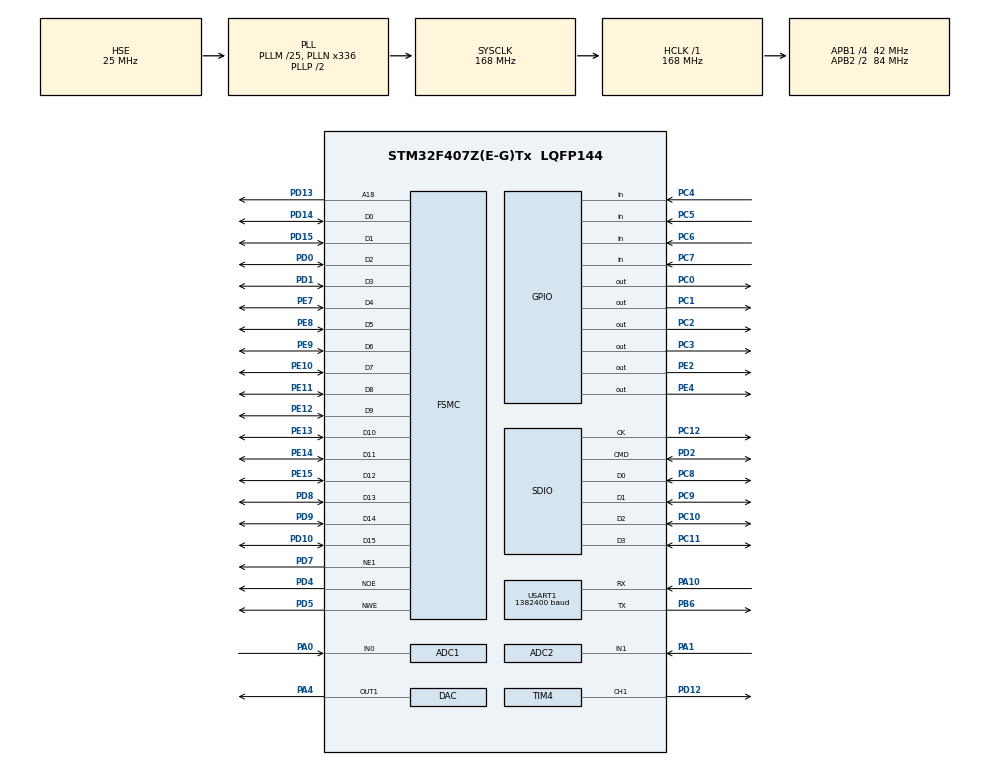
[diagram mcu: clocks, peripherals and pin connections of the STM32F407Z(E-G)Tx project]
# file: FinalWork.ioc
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ADC1.Channel-0\#ChannelRegularConversion=ADC_CHANNEL_0
ADC1.ClockPrescaler=ADC_CLOCK_SYNC_PCLK_DIV4
ADC1.ContinuousConvMode=ENABLE
ADC1.DMAContinuousRequests=ENABLE
ADC1.ExternalTrigConv=ADC_EXTERNALTRIGCONV_T2_TRGO
ADC1.NbrOfConversionFlag=1
ADC1.Rank-0\#ChannelRegularConversion=1
ADC1.SamplingTime-0\#ChannelRegularConversion=ADC_SAMPLETIME_15CYCLES
ADC1.ScanConvMode=DISABLE
ADC1.master=1
ADC2.Channel-1\#ChannelRegularConversion=ADC_CHANNEL_1
ADC2.ClockPrescaler=ADC_CLOCK_SYNC_PCLK_DIV4
ADC2.ExternalTrigConv=ADC_EXTERNALTRIGCONV_T3_TRGO
ADC2.NbrOfConversionFlag=1
ADC2.Rank-1\#ChannelRegularConversion=1
ADC2.SamplingTime-1\#ChannelRegularConversion=ADC_SAMPLETIME_3CYCLES
Dma.ADC1.0.Direction=DMA_PERIPH_TO_MEMORY
Dma.ADC1.0.FIFOMode=DMA_FIFOMODE_DISABLE
Dma.ADC1.0.Instance=DMA2_Stream0
Dma.ADC1.0.MemDataAlignment=DMA_MDATAALIGN_HALFWORD
Dma.ADC1.0.MemInc=DMA_MINC_ENABLE
Dma.ADC1.0.Mode=DMA_NORMAL
Dma.ADC1.0.PeriphDataAlignment=DMA_PDATAALIGN_HALFWORD
Dma.ADC1.0.PeriphInc=DMA_PINC_DISABLE
Dma.ADC1.0.Priority=DMA_PRIORITY_LOW
Dma.ADC2.1.Direction=DMA_PERIPH_TO_MEMORY
Dma.ADC2.1.FIFOMode=DMA_FIFOMODE_DISABLE
Dma.ADC2.1.Instance=DMA2_Stream2
Dma.ADC2.1.MemDataAlignment=DMA_MDATAALIGN_HALFWORD
Dma.ADC2.1.MemInc=DMA_MINC_ENABLE
Dma.ADC2.1.Mode=DMA_NORMAL
Dma.ADC2.1.PeriphDataAlignment=DMA_PDATAALIGN_HALFWORD
Dma.ADC2.1.PeriphInc=DMA_PINC_DISABLE
Dma.ADC2.1.Priority=DMA_PRIORITY_LOW
Dma.Request0=ADC1
Dma.Request1=ADC2
FATFS._FS_RPATH=0
FATFS._STRF_ENCODE=3
FATFS._USE_EXPAND=0
FATFS._USE_FIND=0
FATFS._USE_LFN=0
FSMC.BusTurnAroundDuration1=0
FSMC.DataSetupTime1=24
FSMC.ExtendedAddressSetupTime1=3
FSMC.ExtendedBusTurnAroundDuration1=0
FSMC.ExtendedDataSetupTime1=2
FSMC.ExtendedMode1=FSMC_EXTENDED_MODE_ENABLE
Mcu.Family=STM32F4
Mcu.Name=STM32F407Z(E-G)Tx
Mcu.Package=LQFP144
NVIC.ADC_IRQn=true\:0\:0\:false\:false\:true\:true\:true
NVIC.DMA2_Stream0_IRQn=true\:0\:0\:false\:false\:true\:false\:true
NVIC.DMA2_Stream2_IRQn=true\:0\:0\:false\:false\:true\:false\:true
NVIC.PriorityGroup=NVIC_PRIORITYGROUP_4
NVIC.USART1_IRQn=true\:1\:0\:true\:false\:true\:true\:true
PA0-WKUP.Signal=ADCx_IN0
PA1.Signal=ADCx_IN1
PA10.Mode=Asynchronous
PA10.Signal=USART1_RX
PA13.Mode=Serial_Wire
PA13.Signal=SYS_JTMS-SWDIO
PA14.Mode=Serial_Wire
PA14.Signal=SYS_JTCK-SWCLK
PA4.Signal=COMP_DAC1_group
PB6.Mode=Asynchronous
PB6.Signal=USART1_TX
PC0.Signal=GPIO_Output
PC1.Signal=GPIO_Output
PC10.Mode=SD_4_bits_Wide_bus
PC10.Signal=SDIO_D2
PC11.Mode=SD_4_bits_Wide_bus
PC11.Signal=SDIO_D3
PC12.Mode=SD_4_bits_Wide_bus
PC12.Signal=SDIO_CK
PC2.Signal=GPIO_Output
PC3.Signal=GPIO_Output
PC4.GPIO_PuPd=GPIO_PULLUP
PC4.Signal=GPIO_Input
PC5.GPIO_PuPd=GPIO_PULLUP
PC5.Signal=GPIO_Input
PC6.GPIO_PuPd=GPIO_PULLUP
PC6.Signal=GPIO_Input
PC7.GPIO_PuPd=GPIO_PULLUP
PC7.Signal=GPIO_Input
PC8.Mode=SD_4_bits_Wide_bus
PC8.Signal=SDIO_D0
PC9.Mode=SD_4_bits_Wide_bus
PC9.Signal=SDIO_D1
PD0.Signal=FSMC_D2_DA2
PD1.Signal=FSMC_D3_DA3
PD10.Signal=FSMC_D15_DA15
PD12.Signal=S_TIM4_CH1
PD13.Signal=FSMC_A18
PD14.Signal=FSMC_D0_DA0
PD15.Signal=FSMC_D1_DA1
PD2.Mode=SD_4_bits_Wide_bus
PD2.Signal=SDIO_CMD
PD4.Signal=FSMC_NOE
PD5.Signal=FSMC_NWE
PD7.Mode=NorPsramChipSelect1_1
PD7.Signal=FSMC_NE1
PD8.Signal=FSMC_D13_DA13
PD9.Signal=FSMC_D14_DA14
PE10.Signal=FSMC_D7_DA7
PE11.Signal=FSMC_D8_DA8
PE12.Signal=FSMC_D9_DA9
PE13.Signal=FSMC_D10_DA10
PE14.Signal=FSMC_D11_DA11
PE15.Signal=FSMC_D12_DA12
PE2.Signal=GPIO_Output
PE4.Signal=GPIO_Output
PE7.Signal=FSMC_D4_DA4
PE8.Signal=FSMC_D5_DA5
PE9.Signal=FSMC_D6_DA6
PH0-OSC_IN.Mode=HSE-External-Clock-Source
PH0-OSC_IN.Signal=RCC_OSC_IN
PH1-OSC_OUT.Mode=HSE-External-Clock-Source
PH1-OSC_OUT.Signal=RCC_OSC_OUT
ProjectManager.HeapSize=0x11170
ProjectManager.StackSize=0x11170
ProjectManager.TargetToolchain=MDK-ARM V5.27
RCC.48MHZClocksFreq_Value=48000000
RCC.AHBFreq_Value=168000000
RCC.APB1CLKDivider=RCC_HCLK_DIV4
RCC.APB1Freq_Value=42000000
RCC.APB1TimFreq_Value=84000000
RCC.APB2CLKDivider=RCC_HCLK_DIV2
RCC.APB2Freq_Value=84000000
RCC.APB2TimFreq_Value=168000000
RCC.CortexFreq_Value=168000000
RCC.HCLKFreq_Value=168000000
RCC.HSE_VALUE=25000000
RCC.HSI_VALUE=16000000
RCC.LSE_VALUE=32768
RCC.PLLM=25
RCC.PLLN=336
RCC.PLLQ=7
RCC.PLLSourceVirtual=RCC_PLLSOURCE_HSE
RCC.SYSCLKFreq_VALUE=168000000
RCC.SYSCLKSource=RCC_SYSCLKSOURCE_PLLCLK
RCC.VCOOutputFreq_Value=336000000
SDIO.ClockBypass=SDIO_CLOCK_BYPASS_ENABLE
SDIO.ClockDiv=4
SH.ADCx_IN0.0=ADC1_IN0,IN0
SH.ADCx_IN1.0=ADC2_IN1,IN1
SH.COMP_DAC1_group.0=DAC_OUT1,DAC_OUT1
SH.FSMC_A18.0=FSMC_A18,A18_1
SH.FSMC_D0_DA0.0=FSMC_D0,16b-d1
SH.FSMC_D10_DA10.0=FSMC_D10,16b-d1
SH.FSMC_D11_DA11.0=FSMC_D11,16b-d1
SH.FSMC_D12_DA12.0=FSMC_D12,16b-d1
SH.FSMC_D13_DA13.0=FSMC_D13,16b-d1
SH.FSMC_D14_DA14.0=FSMC_D14,16b-d1
SH.FSMC_D15_DA15.0=FSMC_D15,16b-d1
SH.FSMC_D1_DA1.0=FSMC_D1,16b-d1
SH.FSMC_D2_DA2.0=FSMC_D2,16b-d1
SH.FSMC_D3_DA3.0=FSMC_D3,16b-d1
SH.FSMC_D4_DA4.0=FSMC_D4,16b-d1
SH.FSMC_D5_DA5.0=FSMC_D5,16b-d1
SH.FSMC_D6_DA6.0=FSMC_D6,16b-d1
SH.FSMC_D7_DA7.0=FSMC_D7,16b-d1
SH.FSMC_D8_DA8.0=FSMC_D8,16b-d1
SH.FSMC_D9_DA9.0=FSMC_D9,16b-d1
SH.FSMC_NOE.0=FSMC_NOE,Lcd1
SH.FSMC_NWE.0=FSMC_NWE,Lcd1
SH.S_TIM4_CH1.0=TIM4_CH1,PWM Generation1 CH1
TIM2.Period=200
TIM2.Prescaler=83
TIM2.TIM_MasterOutputTrigger=TIM_TRGO_UPDATE
TIM3.Period=1
TIM3.Prescaler=20480
TIM3.TIM_MasterOutputTrigger=TIM_TRGO_UPDATE
TIM4.Channel-PWM\ Generation1\ CH1=TIM_CHANNEL_1
TIM4.Period=5000
TIM4.Prescaler=83
TIM4.Pulse-PWM\ Generation1\ CH1=1
USART1.BaudRate=1382400
USART1.VirtualMode=VM_ASYNC
VP_FATFS_VS_SDIO.Mode=SDIO
VP_TIM2_VS_ClockSourceINT.Mode=Internal
VP_TIM3_VS_ClockSourceINT.Mode=Internal
VP_TIM4_VS_ClockSourceINT.Mode=Internal
board=custom

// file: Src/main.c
/* USER CODE BEGIN Header */
/**
  ******************************************************************************
  * @file           : main.c
  * @brief          : Main program body
  ******************************************************************************
  * @attention
  *
  * <h2><center>&copy; Copyright (c) 2019 STMicroelectronics.
  * All rights reserved.</center></h2>
  *
  * This software component is licensed by ST under BSD 3-Clause license,
  * the "License"; You may not use this file except in compliance with the
  * License. You may obtain a copy of the License at:
  *                        opensource.org/licenses/BSD-3-Clause
  *
  ******************************************************************************
  */
/* USER CODE END Header */

#include "main.h"
#include "adc.h"
#include "dac.h"
#include "dma.h"
#include "fatfs.h"
#include "sdio.h"
#include "tim.h"
#include "usart.h"
#include "gpio.h"
#include "fsmc.h"

/* USER CODE BEGIN Includes */
#include "UserMain.h"
/* USER CODE END Includes */

void SystemClock_Config(void);

int main(void)
{

  /* MCU Configuration--------------------------------------------------------*/

  /* Reset of all peripherals, Initializes the Flash interface and the Systick. */
  HAL_Init();

  /* Configure the system clock */
  SystemClock_Config();

  /* Initialize all configured peripherals */
  MX_GPIO_Init();
  MX_FSMC_Init();
  MX_ADC1_Init();
  MX_USART1_UART_Init();
  MX_DMA_Init();
  MX_TIM4_Init();
  MX_TIM2_Init();
  MX_ADC2_Init();
  MX_TIM3_Init();
  MX_SDIO_SD_Init();
  MX_FATFS_Init();
  MX_DAC_Init();

  /* Infinite loop */
  /* USER CODE BEGIN WHILE */
  while (1)
  {
		UserMain();
    /* USER CODE END WHILE */

  }
}

void SystemClock_Config(void)
{
  RCC_OscInitTypeDef RCC_OscInitStruct = {0};
  RCC_ClkInitTypeDef RCC_ClkInitStruct = {0};

  /** Configure the main internal regulator output voltage
  */
  __HAL_RCC_PWR_CLK_ENABLE();
  __HAL_PWR_VOLTAGESCALING_CONFIG(PWR_REGULATOR_VOLTAGE_SCALE1);
  /** Initializes the CPU, AHB and APB busses clocks
  */
  RCC_OscInitStruct.OscillatorType = RCC_OSCILLATORTYPE_HSE;
  RCC_OscInitStruct.HSEState = RCC_HSE_BYPASS;
  RCC_OscInitStruct.PLL.PLLState = RCC_PLL_ON;
  RCC_OscInitStruct.PLL.PLLSource = RCC_PLLSOURCE_HSE;
  RCC_OscInitStruct.PLL.PLLM = 25;
  RCC_OscInitStruct.PLL.PLLN = 336;
  RCC_OscInitStruct.PLL.PLLP = RCC_PLLP_DIV2;
  RCC_OscInitStruct.PLL.PLLQ = 7;
  if (HAL_RCC_OscConfig(&RCC_OscInitStruct) != HAL_OK)
  {
    Error_Handler();
  }
  /** Initializes the CPU, AHB and APB busses clocks
  */
  RCC_ClkInitStruct.ClockType = RCC_CLOCKTYPE_HCLK|RCC_CLOCKTYPE_SYSCLK
                              |RCC_CLOCKTYPE_PCLK1|RCC_CLOCKTYPE_PCLK2;
  RCC_ClkInitStruct.SYSCLKSource = RCC_SYSCLKSOURCE_PLLCLK;
  RCC_ClkInitStruct.AHBCLKDivider = RCC_SYSCLK_DIV1;
  RCC_ClkInitStruct.APB1CLKDivider = RCC_HCLK_DIV4;
  RCC_ClkInitStruct.APB2CLKDivider = RCC_HCLK_DIV2;

  if (HAL_RCC_ClockConfig(&RCC_ClkInitStruct, FLASH_LATENCY_5) != HAL_OK)
  {
    Error_Handler();
  }
}

void Error_Handler(void)
{
}

/************************ (C) COPYRIGHT STMicroelectronics *****END OF FILE****/
